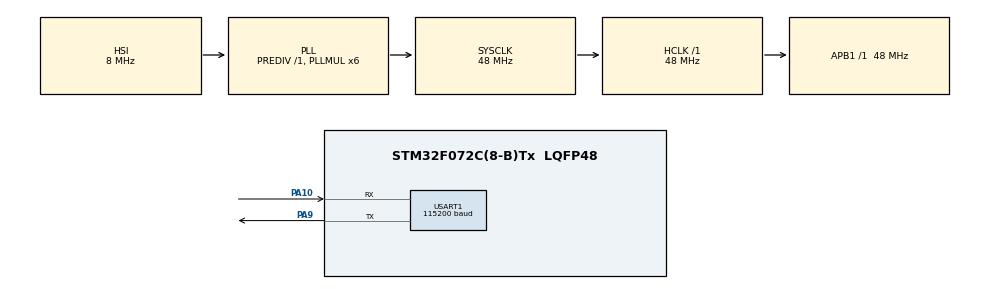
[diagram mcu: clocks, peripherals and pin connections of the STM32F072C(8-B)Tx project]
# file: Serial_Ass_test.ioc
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Mcu.Family=STM32F0
Mcu.Name=STM32F072C(8-B)Tx
Mcu.Package=LQFP48
NVIC.USART1_IRQn=true\:0\:0\:false\:false\:true\:true\:true\:true
PA10.Mode=Asynchronous
PA10.Signal=USART1_RX
PA9.Mode=Asynchronous
PA9.Signal=USART1_TX
PF0-OSC_IN.Mode=HSE-External-Oscillator
PF0-OSC_IN.Signal=RCC_OSC_IN
PF1-OSC_OUT.Mode=HSE-External-Oscillator
PF1-OSC_OUT.Signal=RCC_OSC_OUT
ProjectManager.HeapSize=0x200
ProjectManager.StackSize=0x400
ProjectManager.TargetToolchain=STM32CubeIDE
RCC.AHBFreq_Value=48000000
RCC.APB1Freq_Value=48000000
RCC.APB1TimFreq_Value=48000000
RCC.HCLKFreq_Value=48000000
RCC.PLLMUL=RCC_PLL_MUL6
RCC.SYSCLKFreq_VALUE=48000000
RCC.SYSCLKSource=RCC_SYSCLKSOURCE_PLLCLK
USART1.BaudRate=115200
USART1.VirtualMode-Asynchronous=VM_ASYNC
board=custom

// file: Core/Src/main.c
/* USER CODE BEGIN Header */
/**
  ******************************************************************************
  * @file           : main.c
  * @brief          : Main program body
  ******************************************************************************
  * @attention
  *
  * Copyright (c) 2024 STMicroelectronics.
  * All rights reserved.
  *
  * This software is licensed under terms that can be found in the LICENSE file
  * in the root directory of this software component.
  * If no LICENSE file comes with this software, it is provided AS-IS.
  *
  ******************************************************************************
  */
/* USER CODE END Header */
#include "main.h"
#include "usart.h"
#include "gpio.h"

/* USER CODE BEGIN Includes */
#include "string.h"
/* USER CODE END Includes */

/* USER CODE BEGIN PV */
uint8_t uart_buf[128];
uint8_t buf[128];
uint8_t uart_tx[20] = {0x06, 0x01, 0x42, 0x41, 0xfb, 0x03};
/* USER CODE END PV */

void SystemClock_Config(void);

/* USER CODE BEGIN 0 */
//uint8_t data[6] = {0x06, 0x01, 0x42 ,0x41, 0xfb, 0x03};
/* USER CODE END 0 */

int main(void)
{

  /* MCU Configuration--------------------------------------------------------*/

  /* Reset of all peripherals, Initializes the Flash interface and the Systick. */
  HAL_Init();

  /* Configure the system clock */
  SystemClock_Config();

  /* Initialize all configured peripherals */
  MX_GPIO_Init();
  MX_USART1_UART_Init();
  /* USER CODE BEGIN 2 */
  //HAL_UARTEx_ReceiveToIdle_IT(&huart1, uart_buf, 128);
  /* USER CODE END 2 */

  /* Infinite loop */
  /* USER CODE BEGIN WHILE */
  while (1)
  {
//	  __HAL_UART_ENABLE_IT(&huart1, UART_IT_IDLE);// 使能空闲中断
//	  HAL_UART_Receive_IT(&huart1, buf, 1);
	  HAL_UART_Transmit(&huart1, uart_tx, 6, 100);
	  HAL_Delay(1000);
    /* USER CODE END WHILE */

  }
}

void SystemClock_Config(void)
{
  RCC_OscInitTypeDef RCC_OscInitStruct = {0};
  RCC_ClkInitTypeDef RCC_ClkInitStruct = {0};
  RCC_PeriphCLKInitTypeDef PeriphClkInit = {0};

  /** Initializes the RCC Oscillators according to the specified parameters
  * in the RCC_OscInitTypeDef structure.
  */
  RCC_OscInitStruct.OscillatorType = RCC_OSCILLATORTYPE_HSI;
  RCC_OscInitStruct.HSIState = RCC_HSI_ON;
  RCC_OscInitStruct.HSICalibrationValue = RCC_HSICALIBRATION_DEFAULT;
  RCC_OscInitStruct.PLL.PLLState = RCC_PLL_ON;
  RCC_OscInitStruct.PLL.PLLSource = RCC_PLLSOURCE_HSI;
  RCC_OscInitStruct.PLL.PLLMUL = RCC_PLL_MUL6;
  RCC_OscInitStruct.PLL.PREDIV = RCC_PREDIV_DIV1;
  if (HAL_RCC_OscConfig(&RCC_OscInitStruct) != HAL_OK)
  {
    Error_Handler();
  }

  /** Initializes the CPU, AHB and APB buses clocks
  */
  RCC_ClkInitStruct.ClockType = RCC_CLOCKTYPE_HCLK|RCC_CLOCKTYPE_SYSCLK
                              |RCC_CLOCKTYPE_PCLK1;
  RCC_ClkInitStruct.SYSCLKSource = RCC_SYSCLKSOURCE_PLLCLK;
  RCC_ClkInitStruct.AHBCLKDivider = RCC_SYSCLK_DIV1;
  RCC_ClkInitStruct.APB1CLKDivider = RCC_HCLK_DIV1;

  if (HAL_RCC_ClockConfig(&RCC_ClkInitStruct, FLASH_LATENCY_1) != HAL_OK)
  {
    Error_Handler();
  }
  PeriphClkInit.PeriphClockSelection = RCC_PERIPHCLK_USART1;
  PeriphClkInit.Usart1ClockSelection = RCC_USART1CLKSOURCE_PCLK1;
  if (HAL_RCCEx_PeriphCLKConfig(&PeriphClkInit) != HAL_OK)
  {
    Error_Handler();
  }
}

void Error_Handler(void)
{
  __disable_irq();
  while (1)
  {
  }
}
